# R7FA2L209 register map
Vendor: Renesas Electronics Corporation; Series: RA2; File version: 1.10.02
CPU: CM23 r1p0, little endian, MPU, no FPU, VTOR, 2 interrupt priority bits, 32 interrupts
Registers are 8-bit, read-write, reset 0x0 unless marked. A register's access mark holds for its fields unless they carry their own. Offsets are from the block's base; [hi:lo] are bit positions; 'fields as' and 'values as' point back to an identical list.

## USBCC — USB type-C Controller 2.0 Module
Base 0x40091000
0x00 TCC 32-bit reset 0x1 — TYPE-C Control Register
  [31] RESET — Software Reset for USB Type-C Interface
    0=In writing: Invalid (writing 0 has no effect). In reading: Normal operation is in progress, or the USB Type-C interface software reset has completed.; 1=In writing: Initialize registers to be reset in the USB Type-C interface. In reading: USB Type-C interface software reset is in progress.
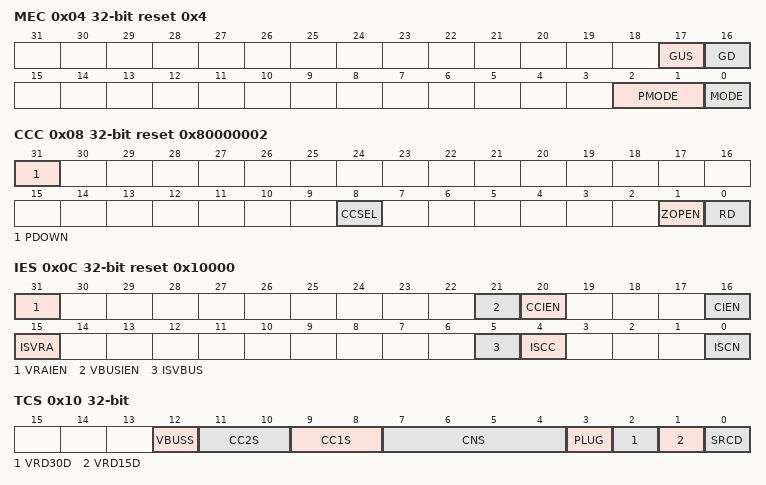
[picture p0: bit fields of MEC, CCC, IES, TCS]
0x04 MEC 32-bit reset 0x4 — Mode Setting and State Control Register
  [17] GUS wo
    0=Invalid (writing 0 has no effect); 1=Direct connection state to Unattached.SNK from any state
  [16] GD wo
    0=Invalid (writing 0 has no effect); 1=Direct connection state to Disabled from any state
  [2:1] PMODE — Source Current Detection Mode
    0=Detect Default USB source; 1=Detect Default USB and 1.5A source; 2=Detect Default USB, 1.5A, and 3.0A source; 3=Setting prohibited
  [0] MODE — Connection State Mode
    0=Sink-only mode; 1=USB 2.0-only Sink mode
0x08 CCC 32-bit reset 0x80000002 — CC-PHY Control Register
  [31] PDOWN
    0=Not power down; 1=Power down
  [8] CCSEL ro
    0=vRd-1.5 or vRd-3.0 detection is applied on USB_CC1; 1=vRd-1.5 or vRd-3.0 detection is applied on USB_CC2
  [1] ZOPEN — zOPEN Control
    0=zOPEN off; 1=zOPEN on
  [0] RD ro — RD Status
    0=RD off; 1=RD on
0x0C IES 32-bit reset 0x10000 — Interrupt Enable Control and Status Register
  [31] VRAIEN
    0=No interrupt occurs when the ISVRA flag is set to 1; 1=Interrupt occurs when the ISVRA flag is set to 1
  [21] VBUSIEN
    0=No interrupt occurs when the ISVBUS flag is set to 1; 1=Interrupt occurs when the ISVBUS flag is set to 1
  [20] CCIEN
    0=No interrupt occurs when the ISCC flag is set to 1; 1=Interrupt occurs when the ISCC flag is set to 1
  [16] CIEN
    0=No interrupt occurs when the ISCN flag is set to 1; 1=Interrupt occurs when the ISCN flag is set to 1
  [15] ISVRA
    0=In writing: Invalid (writing 0 has no effect). In reading: No source (Rp) is detected on CC1 or CC2, or this bit has already been cleared by software.; 1=In writing: Set this bit to 0. In reading: Source (Rp) is detected on CC1 or CC2.
  [5] ISVBUS
    0=In writing: Invalid (writing 0 has no effect). In reading: No VBUS status change occurred or this bit has already been cleared by software.; 1=In writing: Set this bit to 0. In reading: VBUS status changed.
  [4] ISCC — CC Status Change Flag
    0=In writing: Invalid (writing 0 has no effect). In reading: No CC1/CC2 status change occurred or this bit has already been cleared by software.; 1=In writing: Set this bit to 0. In reading: CC1/CC2 status changed.
  [0] ISCN — Connection Status Change Flag
    0=In writing: Invalid (writing 0 has no effect). In reading: No connection status change occurred or this bit has already been cleared by software.; 1=In writing: Set this bit to 0. In reading: Connection status changed.
0x10 TCS 32-bit ro — Type-CC Connection State and Status Register
  [12] VBUSS
    0=VBUS is off; 1=VBUS is on
  [11:10] CC2S — Status of CC2
    0=Open (below maximum vRa); 1=Default USB (above minimum vRd-Connect); 2=Power1.5 (voltage above minimum vRd-Connect, and within the range of vRd-1.5); 3=Power3.0 (voltage above minimum vRd-Connect, and within the range of vRd-3.0)
  [9:8] CC1S
    values as CC2S
  [7:4] CNS
    0=Disabled; 1=Unattached.SNK; 2=AttachWait.SNK; 4=Attached.SNK (PowerDefault.SNK); 5=Attached.SNK (Power1.5.SNK); 6=Attached.SNK (Power3.0.SNK); other=Others (Undefined)
  [3] PLUG
    0=CC1 is connected; 1=CC2 is connected
  [2] VRD30D
    0=Power3.0 source is not connected; 1=Power3.0 Source is connected
  [1] VRD15D — Detection of Power1.5 Source Connection
    0=Power1.5 source is not connected; 1=Power1.5 source is connected
  [0] SRCD — Detection of Source Connection
    0=Source is not connected (connection status not in Attached.SNK); 1=Source is connected (connection status in Attached.SNK)
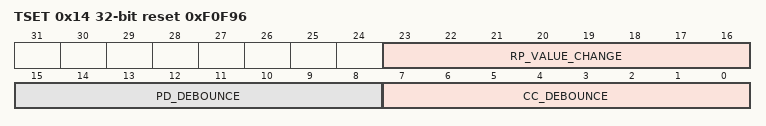
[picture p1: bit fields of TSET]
0x14 TSET 32-bit reset 0xF0F96 — Type-C Related Timer Value Setting Register
  [23:16] RP_VALUE_CHANGE — tRpValueChange value based on 1 ms unit.
  [15:8] PD_DEBOUNCE — tPDDebounce value based on 1 ms unit.
  [7:0] CC_DEBOUNCE — tCCDebounce value based on 1 ms unit.
